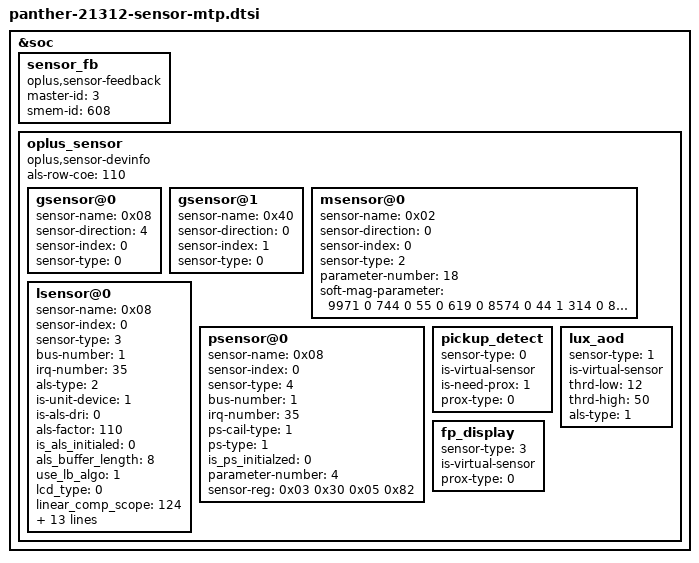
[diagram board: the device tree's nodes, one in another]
&soc {
        sensor_fb {
		compatible = "oplus,sensor-feedback";
		master-id  = <3>;
		smem-id    = <608>;
	};
	oplus_sensor {
			compatible = "oplus,sensor-devinfo";
			als-row-coe = <110>;
			/*enum {LSM6DSM = 0x01, BMI160 = 0x02, LSM6DS3 = 0x04, BMI260 = 0x08};*/
			gsensor@0 {
					sensor-name = <0x08>;//BMI260
					sensor-direction = <4>;
					sensor-index = <0>;//source num
					sensor-type = <0>;//OPPO_ACCEL
			};
			gsensor@1 {
					sensor-name = <0x40>;//ICM4X607
					sensor-direction = <0>;
					sensor-index = <1>;//source num
					sensor-type = <0>;//OPPO_ACCEL
			};
			/* enum {AKM0991X = 0x01, MMC5603 = 0x02, MXG4300 = 0x04};*/
			msensor@0 {
					sensor-name = <0x02>;//MMC5603
					sensor-direction = <0>;
					sensor-index = <0>;
					sensor-type = <2>;//OPPO_MAG
					parameter-number= <18>;
					soft-mag-parameter = <9971 0 744 0 55 0 619 0 8574 0 44 1 314 0 850 1 9931 0>;//e00 sign e01 sign...
			};
			/*enum {STK3A5X=0x01,TCS3701=0x02,TCS3408=0x04,STK326X=0x08,MN78911=0x10};*/
			/*enum {NORMAL=0x01,UNDER_LCD=0x02,VIRTUAL_UNDER_LCD=0x03}*/
			lsensor@0 {
					sensor-name = <0x08>;//stk326x
					sensor-index = <0>;
					sensor-type = <3>;//OPLUS_ALS
					bus-number = <1>;
					irq-number = <35>;
					als-type = <2>;//UNDER_LCD
					is-unit-device = <1>;
					is-als-dri = <0>;
					als-factor = <110>;
					is_als_initialed = <0>;
					als_buffer_length = <8>;
					use_lb_algo = <1>;
					lcd_type = <0>;
					linear_comp_scope = <124>;
					linear_comp_intercept = <14069>;
					temp_lux = <10>;
					coef = <1330>;
					bal_coef = <280>;
					ir_coef_stage_0 = <64>;
					ir_coef_stage_1 = <89>;
					ir_coef_stage_2 = <115>;
					ir_coef_stage_3 = <127>;
					ir_coef_val_0 = <1000>;
					ir_coef_val_1 = <440>;
					ir_coef_val_2 = <290>;
					ir_coef_val_3 = <190>;
					ir_coef_val_4 = <170>;
			};
			psensor@0 {
					sensor-name = <0x08>;//stk326x
					sensor-index = <0>;
					sensor-type = <4>;//OPLUS_PROXIMITY
					bus-number = <1>;
					irq-number = <35>;
					ps-cail-type = <1>;
					ps-type = <1>;
					is_ps_initialzed = <0>;
					parameter-number = <4>;
					sensor-reg = <0x03 0x30
                                                      0x05 0x82>; //override special reg
			};
			/*virtual sensor
			enum sensor_algo_id {
					OPPO_PICKUP_DETECT,
					OPPO_LUX_AOD,
					OPPO_TP_GESTURE,
					OPPO_FP_DISPLAY,
					OPPO_FREE_FALL,
					OPPO_CAMERA_PROTECT,
					SENSOR_ALGO_NUM
			}*/
			pickup_detect {
					sensor-type = <0>; //OPPO_PICKUP_DETECT
					is-virtual-sensor;
					is-need-prox = <1>;
					prox-type = <0>; // 0 - proximity; 1 - proximity_fake
			};
			lux_aod {
					sensor-type = <1>; //OPPO_LUX_AOD
					is-virtual-sensor;
					thrd-low = <12>;
					thrd-high = <50>;
					als-type = <1>; // 0 - ambient_light; 1 - wise_light
			};
			fp_display {
					sensor-type = <3>; //OPPO_FP_DISPLAY
					is-virtual-sensor;
					prox-type = <0>; // 0 - proximity; 1 - proximity_fake
			};
	};
};
